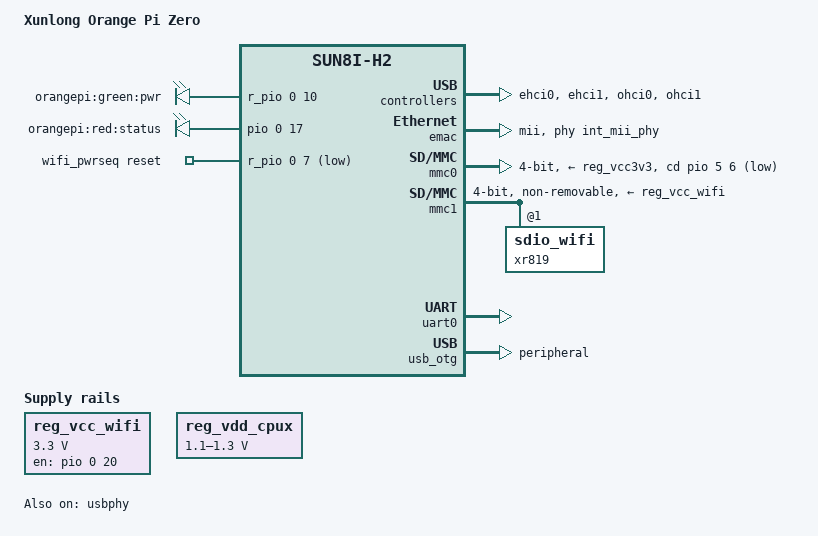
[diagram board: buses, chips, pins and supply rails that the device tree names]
/dts-v1/;
#include "sun8i-h3.dtsi"
#include "sunxi-common-regulators.dtsi"
#include <dt-bindings/gpio/gpio.h>
#include <dt-bindings/input/input.h>
/ {
	model = "Xunlong Orange Pi Zero";
	compatible = "xunlong,orangepi-zero", "allwinner,sun8i-h2-plus";
	aliases {
		serial0 = &uart0;
		ethernet0 = &emac;
		ethernet1 = &xr819;
	};
	chosen {
		stdout-path = "serial0:115200n8";
	};
	leds {
		compatible = "gpio-leds";
		pwr_led {
			label = "orangepi:green:pwr";
			gpios = <&r_pio 0 10 GPIO_ACTIVE_HIGH>;
			default-state = "on";
		};
		status_led {
			label = "orangepi:red:status";
			gpios = <&pio 0 17 GPIO_ACTIVE_HIGH>;
		};
	};
	reg_vcc_wifi: reg_vcc_wifi {
		compatible = "regulator-fixed";
		regulator-min-microvolt = <3300000>;
		regulator-max-microvolt = <3300000>;
		regulator-name = "vcc-wifi";
		enable-active-high;
		gpio = <&pio 0 20 GPIO_ACTIVE_HIGH>;
	};
	reg_vdd_cpux: vdd-cpux-regulator {
		compatible = "regulator-gpio";
		regulator-name = "vdd-cpux";
		regulator-type = "voltage";
		regulator-boot-on;
		regulator-always-on;
		regulator-min-microvolt = <1100000>;
		regulator-max-microvolt = <1300000>;
		regulator-ramp-delay = <50>;  
		gpios = <&r_pio 0 6 GPIO_ACTIVE_HIGH>;  
		enable-active-high;
		gpios-states = <1>;
		states = <1100000 0>, <1300000 1>;
	};
	wifi_pwrseq: wifi_pwrseq {
		compatible = "mmc-pwrseq-simple";
		reset-gpios = <&r_pio 0 7 GPIO_ACTIVE_LOW>;
		post-power-on-delay-ms = <200>;
	};
};
&cpu0 {
	cpu-supply = <&reg_vdd_cpux>;
};
&ehci0 {
	status = "okay";
};
&ehci1 {
	status = "okay";
};
&emac {
	phy-handle = <&int_mii_phy>;
	phy-mode = "mii";
	allwinner,leds-active-low;
	status = "okay";
};
&mmc0 {
	vmmc-supply = <&reg_vcc3v3>;
	bus-width = <4>;
	cd-gpios = <&pio 5 6 GPIO_ACTIVE_LOW>;  
	status = "okay";
};
&mmc1 {
	vmmc-supply = <&reg_vcc_wifi>;
	mmc-pwrseq = <&wifi_pwrseq>;
	bus-width = <4>;
	non-removable;
	status = "okay";
	xr819: sdio_wifi@1 {
		reg = <1>;
	};
};
&ohci0 {
	status = "okay";
};
&ohci1 {
	status = "okay";
};
&spi0 {
	status = "disabled";
	flash@0 {
		#address-cells = <1>;
		#size-cells = <1>;
		compatible = "mxicy,mx25l1606e", "jedec,spi-nor";
		reg = <0>;
		spi-max-frequency = <40000000>;
	};
};
&uart0 {
	pinctrl-names = "default";
	pinctrl-0 = <&uart0_pa_pins>;
	status = "okay";
};
&uart1 {
	pinctrl-names = "default";
	pinctrl-0 = <&uart1_pins>;
	status = "disabled";
};
&uart2 {
	pinctrl-names = "default";
	pinctrl-0 = <&uart2_pins>;
	status = "disabled";
};
&usb_otg {
	dr_mode = "peripheral";
	status = "okay";
};
&usbphy {
	status = "okay";
	usb0_id_det-gpios = <&pio 6 12 GPIO_ACTIVE_HIGH>;  
};
